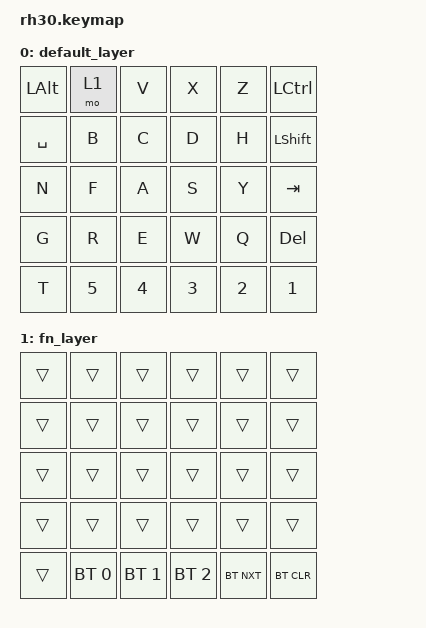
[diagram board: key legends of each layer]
#include <behaviors.dtsi>
#include <dt-bindings/zmk/keys.h>
#include <dt-bindings/zmk/bt.h>

/ {
    keymap {
        compatible = "zmk,keymap";

        default_layer {
            bindings = 
                &kp LALT  &mo 1     &kp V     &kp X     &kp Z     &kp LCTRL
                &kp SPACE &kp B     &kp C     &kp D     &kp H     &kp LSHFT
                &kp N     &kp F     &kp A     &kp S     &kp Y     &kp TAB
                &kp G     &kp R     &kp E     &kp W     &kp Q     &kp DEL
                &kp T     &kp N5    &kp N4    &kp N3    &kp N2    &kp N1
            >;
        };

        fn_layer {
            bindings = 
                &trans        &trans        &trans        &trans        &trans        &trans
                &trans        &trans        &trans        &trans        &trans        &trans
                &trans        &trans        &trans        &trans        &trans        &trans
                &trans        &trans        &trans        &trans        &trans        &trans
                &trans        &bt BT_SEL 0  &bt BT_SEL 1  &bt BT_SEL 2  &bt BT_NXT  &bt BT_CLR
            >;
        };
    };
};
